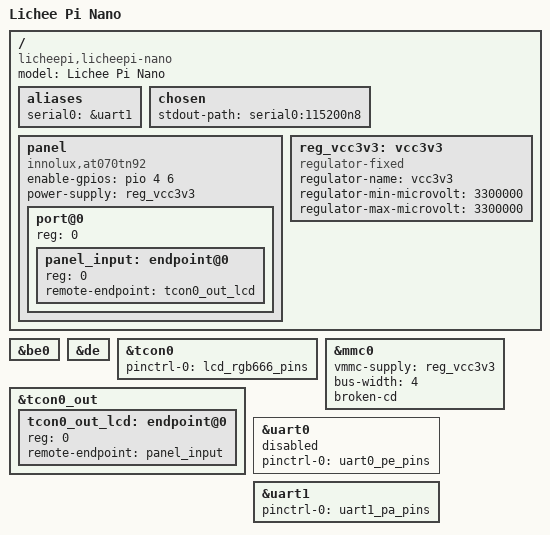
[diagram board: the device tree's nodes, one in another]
// SPDX-License-Identifier: (GPL-2.0+ OR X11)
/*
 * Copyright 2018 Icenowy Zheng <icenowy@aosc.io>
 */

/dts-v1/;
#include "suniv-f1c100s.dtsi"
#include <dt-bindings/gpio/gpio.h>

/ {
	model = "Lichee Pi Nano";
	compatible = "licheepi,licheepi-nano", "allwinner,suniv-f1c100s";

	aliases {
		serial0 = &uart1;
	};

	chosen {
		stdout-path = "serial0:115200n8";
	};

	panel: panel {
		compatible = "innolux,at070tn92", "simple-panel";
		#address-cells = <1>;
		#size-cells = <0>;
		enable-gpios = <&pio 4 6 GPIO_ACTIVE_HIGH>;
		power-supply = <&reg_vcc3v3>;

		port@0 {
			reg = <0>;
			#address-cells = <1>;
			#size-cells = <0>;

			panel_input: endpoint@0 {
				reg = <0>;
				remote-endpoint = <&tcon0_out_lcd>;
			};
		};
	};

	reg_vcc3v3: vcc3v3 {
		compatible = "regulator-fixed";
		regulator-name = "vcc3v3";
		regulator-min-microvolt = <3300000>;
		regulator-max-microvolt = <3300000>;
	};
};

&be0 {
	status = "okay";
};

&de {
	status = "okay";
};

&tcon0 {
	pinctrl-names = "default";
	pinctrl-0 = <&lcd_rgb666_pins>;
	status = "okay";
};

&tcon0_out {
	tcon0_out_lcd: endpoint@0 {
		reg = <0>;
		remote-endpoint = <&panel_input>;
	};
};

&mmc0 {
	vmmc-supply = <&reg_vcc3v3>;
	bus-width = <4>;
	broken-cd;
	status = "okay";
};

&uart0 {
	pinctrl-names = "default";
	pinctrl-0 = <&uart0_pe_pins>;
	status = "disabled";
};

&uart1 {
	pinctrl-names = "default";
	pinctrl-0 = <&uart1_pa_pins>;
	status = "okay";
};
